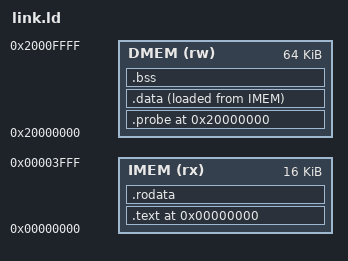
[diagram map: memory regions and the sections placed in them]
/*==============================================================================
 * File        : link.ld
 * Description : FreeRTOS 在本 RV32 核上的链接脚本，内存布局与 riscv_soc.sv
 *               的地址映射严格对齐：
 *                 IMEM  0x0000_0000，16 KB：存放代码、只读数据，以及 .data
 *                       的加载镜像（LMA），复位 PC 从这里开始
 *                 DMEM  0x2000_0000，64 KB：存放可写数据 .data/.bss、FreeRTOS
 *                       堆、启动栈，.data 的运行地址（VMA）在此
 *               启动文件 startup.S 依据本脚本导出的符号完成 .data 拷贝与
 *               .bss 清零。
 *============================================================================*/
OUTPUT_ARCH( "riscv" )
ENTRY( _start )

/*------------------------------------------------------------------------------
 * 内存区域定义
 *----------------------------------------------------------------------------*/
MEMORY
{
    IMEM (rx)  : ORIGIN = 0x00000000, LENGTH = 16K
    DMEM (rw)  : ORIGIN = 0x20000000, LENGTH = 64K
}

/* 启动栈（main 运行及调度器启动前使用，任务栈由 FreeRTOS 在堆中分配） */
__stack_size = 1024;

SECTIONS
{
    /*--------------------------------------------------------------------------
     * 代码段：放在 IMEM 起始，启动入口 .text.init 最先排布
     *------------------------------------------------------------------------*/
    .text ORIGIN( IMEM ) :
    {
        KEEP( *(.text.init) )
        *(.text)
        *(.text.*)
        . = ALIGN(4);
    } > IMEM

    /*--------------------------------------------------------------------------
     * 只读数据段：紧随代码，仍在 IMEM
     *------------------------------------------------------------------------*/
    .rodata :
    {
        . = ALIGN(4);
        *(.rodata)
        *(.rodata.*)
        . = ALIGN(4);
    } > IMEM

    /*--------------------------------------------------------------------------
     * 已初始化可写数据：
     *   运行地址 VMA = DMEM 起始；加载地址 LMA 自动紧随 .rodata 落在 IMEM，
     *   startup.S 从 LMA 拷贝到 VMA。
     *------------------------------------------------------------------------*/
    /*--------------------------------------------------------------------------
     * 探测/观测段：固定在 DMEM 最前，testbench 可按 dmem_mem 字索引直接监测
     *------------------------------------------------------------------------*/
    .probe ORIGIN( DMEM ) :
    {
        . = ALIGN(4);
        _probe_start = .;
        KEEP( *(.probe) )
        . = ALIGN(4);
    } > DMEM

    .data :
    {
        . = ALIGN(4);
        _sdata = .;
        *(.data)
        *(.data.*)
        *(.sdata)
        *(.sdata.*)
        . = ALIGN(4);
        _edata = .;
    } > DMEM AT> IMEM

    /* .data 加载镜像起始地址（startup 拷贝源） */
    _sidata = LOADADDR(.data);

    /* 全局指针：指向小数据区中心，gp 相对寻址覆盖其 ±0x800 范围 */
    __global_pointer$ = ORIGIN( DMEM ) + 0x800;

    /*--------------------------------------------------------------------------
     * 未初始化数据段 .bss：位于 DMEM，startup 负责清零
     *  FreeRTOS 的静态堆 ucHeap、ISR 栈等均归入此段
     *------------------------------------------------------------------------*/
    .bss :
    {
        . = ALIGN(16);
        _sbss = .;
        __bss_start__ = .;
        *(.bss)
        *(.bss.*)
        *(.sbss)
        *(.sbss.*)
        *(COMMON)
        . = ALIGN(16);
        _ebss = .;
        __bss_end__ = .;
    } > DMEM

    /*--------------------------------------------------------------------------
     * 栈顶：DMEM 末尾，栈向下生长
     *------------------------------------------------------------------------*/
    . = ORIGIN( DMEM ) + LENGTH( DMEM );
    _stack_top   = .;
    __stack_top  = .;

    /* 丢弃裸机不需要的段，节省 IMEM 空间 */
    /DISCARD/ :
    {
        *(.comment)
        *(.note*)
        *(.eh_frame)
        *(.riscv.attributes)
    }
}
